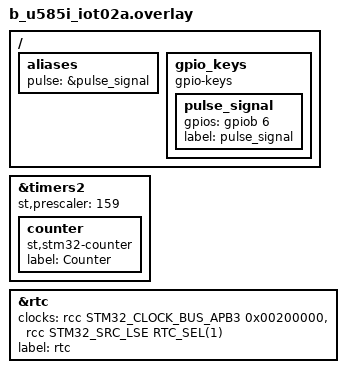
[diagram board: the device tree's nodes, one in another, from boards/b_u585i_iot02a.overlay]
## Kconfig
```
# Config for timer pulse sample

source "Kconfig.zephyr"
```

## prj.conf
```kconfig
CONFIG_COUNTER=y
CONFIG_COUNTER_TIMER_STM32=y
CONFIG_SYS_CLOCK_TICKS_PER_SEC=1000
```

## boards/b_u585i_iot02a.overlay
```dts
&timers2 {
	st,prescaler = <159>;

	counter {
		compatible = "st,stm32-counter";
		label = "Counter";
		status = "okay";
	};
};

&rtc {
	/delete-property/ clocks;
        status = "okay";
        clocks = <&rcc STM32_CLOCK_BUS_APB3 0x00200000>,
                <&rcc STM32_SRC_LSE RTC_SEL(1)>;
        label = "rtc";
};

/ {
    aliases {
	pulse = &pulse_signal;
    };

    gpio_keys {
        compatible = "gpio-keys";

        pulse_signal: pulse_signal {
                gpios = <&gpiob 6 GPIO_PULL_DOWN>;
                label = "pulse_signal";
        };
    };
};
```

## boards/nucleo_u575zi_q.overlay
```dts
&timers2 {
	st,prescaler = <159>;

	counter {
		compatible = "st,stm32-counter";
		label = "Counter";
		status = "okay";
	};
};

&rtc {
	/delete-property/ clocks;
        status = "okay";
        clocks = <&rcc STM32_CLOCK_BUS_APB3 0x00200000>,
		 <&rcc STM32_SRC_LSE RTC_SEL(1)>;
        label = "rtc";
};

/ {
    aliases {
        pulse = &pulse_signal;
    };

    gpio_keys {
        compatible = "gpio-keys";

        pulse_signal: pulse_signal {
                gpios = <&gpiob 6 GPIO_PULL_DOWN>;
                label = "pulse_signal";
        };
    };
};
```

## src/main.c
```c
/*
 * Copyright (c) 2019 Linaro Limited
 *
 * SPDX-License-Identifier: Apache-2.0
 */

#include <zephyr/kernel.h>
#include <zephyr/drivers/gpio.h>
#include <zephyr/device.h>
#include <zephyr/drivers/counter.h>
#include <zephyr/sys/printk.h>

#define DELAY 1000
#define ALARM_CHANNEL_ID 0
#define LED0_NODE DT_ALIAS(pulse)

static const struct gpio_dt_spec led = GPIO_DT_SPEC_GET(LED0_NODE, gpios);
struct counter_alarm_cfg alarm_cfg;
uint32_t* TIM2_CCR1 = (uint32_t*)0x40000034;

#if defined(CONFIG_COUNTER_RTC0)
#define TIMER DT_NODELABEL(rtc0)
//#elif defined(CONFIG_COUNTER_RTC_STM32)
//#define TIMER DT_INST(0, st_stm32_rtc)
#elif defined(CONFIG_COUNTER_RTC_STM32)
//#define TIMER DT_LABEL( DT_INST( 0, st_stm32_counter ) )
#define TIMER DT_INST( 0, st_stm32_counter )
#endif


static void test_counter_interrupt_fn(const struct device *counter_dev,
				      uint8_t chan_id, uint32_t ticks,
				      void *user_data)
{
	/*
	struct counter_alarm_cfg *config = user_data;
	uint32_t now_ticks;
	uint64_t now_usec;
	int now_sec;
	int err;

	err = counter_get_value(counter_dev, &now_ticks);
	if (err) {
		printk("Failed to read counter value (err %d)", err);
		return;
	}

	now_usec = counter_ticks_to_us(counter_dev, now_ticks);
	now_sec = (int)(now_usec / USEC_PER_SEC);

	printk("!!! Alarm !!!\n");
	printk("Now: %u\n", now_sec);

	/* Set a new alarm with a double length duration */
	/*
	config->ticks = config->ticks * 2U;

	printk("Set alarm in %u sec (%u ticks)\n",
	       (uint32_t)(counter_ticks_to_us(counter_dev,
					   config->ticks) / USEC_PER_SEC),
	       config->ticks);
	*/
	counter_set_channel_alarm(counter_dev, ALARM_CHANNEL_ID,
					user_data);
	gpio_pin_toggle_dt(&led);
	
	/*
	if (err != 0) {
		printk("Alarm could not be set\n");
	}
	*/
}

void main(void)
{
	gpio_pin_configure_dt(&led, GPIO_OUTPUT_ACTIVE);
	const struct device *const counter_dev = DEVICE_DT_GET(TIMER);
	int err;
	uint32_t reg = 0;
	
	printk("Counter alarm sample\n\n");

	if (!device_is_ready(counter_dev)) {
		printk("device not ready.\n");
		return;
	}

	counter_start(counter_dev);

	alarm_cfg.flags = 0;
	alarm_cfg.ticks = counter_us_to_ticks(counter_dev, DELAY);
	alarm_cfg.callback = test_counter_interrupt_fn;
	alarm_cfg.user_data = &alarm_cfg;

	err = counter_set_channel_alarm(counter_dev, ALARM_CHANNEL_ID,
					&alarm_cfg);
	reg = *TIM2_CCR1;
	printk("Set alarm in %u sec (%u ticks)\n",
	       (uint32_t)(counter_ticks_to_us(counter_dev,
					   alarm_cfg.ticks) / USEC_PER_SEC),
	       alarm_cfg.ticks);
	printk("Timer Control CCR1 = %d \n", reg);

	if (-EINVAL == err) {
		printk("Alarm settings invalid\n");
	} else if (-ENOTSUP == err) {
		printk("Alarm setting request not supported\n");
	} else if (err != 0) {
		printk("Error\n");
	}

	while (1) {
		k_sleep(K_FOREVER);
	}
}
```
